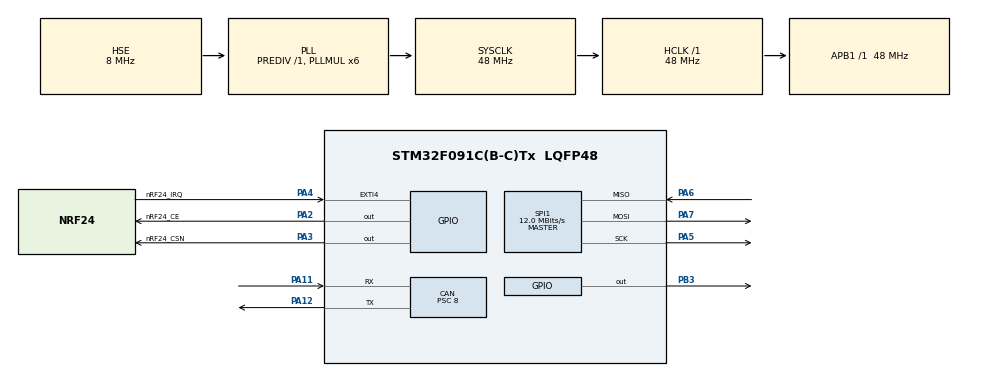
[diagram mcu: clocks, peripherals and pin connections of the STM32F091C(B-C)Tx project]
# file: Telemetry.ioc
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CAN.ABOM=ENABLE
CAN.BS1=CAN_BS1_16TQ
CAN.BS2=CAN_BS2_7TQ
CAN.CalculateTimeBit=4000
CAN.CalculateTimeQuantum=166.66666666666666
CAN.Prescaler=8
CAN.SJW=CAN_SJW_3TQ
Mcu.Family=STM32F0
Mcu.Name=STM32F091C(B-C)Tx
Mcu.Package=LQFP48
NVIC.CEC_CAN_IRQn=true\:0\:0\:false\:false\:true\:true
NVIC.TIM14_IRQn=true\:0\:0\:false\:false\:true\:true
NVIC.TIM16_IRQn=true\:0\:0\:false\:false\:true\:true
NVIC.TIM17_IRQn=true\:0\:0\:false\:false\:true\:true
PA11.Mode=Master
PA11.Signal=CAN_RX
PA12.Mode=Master
PA12.Signal=CAN_TX
PA2.GPIO_Label=nRF24_CE
PA2.GPIO_Speed=GPIO_SPEED_FREQ_HIGH
PA2.Signal=GPIO_Output
PA3.GPIO_Label=nRF24_CSN
PA3.GPIO_Speed=GPIO_SPEED_FREQ_HIGH
PA3.PinState=GPIO_PIN_SET
PA3.Signal=GPIO_Output
PA4.GPIO_Label=nRF24_IRQ
PA4.GPIO_ModeDefaultEXTI=GPIO_MODE_IT_FALLING
PA4.Signal=GPXTI4
PA5.Mode=Full_Duplex_Master
PA5.Signal=SPI1_SCK
PA6.Mode=Full_Duplex_Master
PA6.Signal=SPI1_MISO
PA7.Mode=Full_Duplex_Master
PA7.Signal=SPI1_MOSI
PB3.Signal=GPIO_Output
PF0-OSC_IN.Mode=HSE-External-Oscillator
PF0-OSC_IN.Signal=RCC_OSC_IN
PF1-OSC_OUT.Mode=HSE-External-Oscillator
PF1-OSC_OUT.Signal=RCC_OSC_OUT
ProjectManager.HeapSize=0x200
ProjectManager.StackSize=0x400
ProjectManager.TargetToolchain=TrueSTUDIO
RCC.AHBFreq_Value=48000000
RCC.APB1Freq_Value=48000000
RCC.APB1TimFreq_Value=48000000
RCC.EnbaleCSS=true
RCC.HCLKFreq_Value=48000000
RCC.PLLMUL=RCC_PLL_MUL6
RCC.PLLSourceVirtual=RCC_PLLSOURCE_HSE
RCC.SYSCLKFreq_VALUE=48000000
RCC.SYSCLKSource=RCC_SYSCLKSOURCE_PLLCLK
SPI1.BaudRatePrescaler=SPI_BAUDRATEPRESCALER_4
SPI1.CalculateBaudRate=12.0 MBits/s
SPI1.DataSize=SPI_DATASIZE_8BIT
SPI1.Direction=SPI_DIRECTION_2LINES
SPI1.Mode=SPI_MODE_MASTER
SPI1.VirtualType=VM_MASTER
TIM14.ClockDivision=TIM_CLOCKDIVISION_DIV4
TIM14.Period=999
TIM14.Prescaler=11
TIM16.ClockDivision=TIM_CLOCKDIVISION_DIV4
TIM16.Period=9999
TIM16.Prescaler=11
TIM17.ClockDivision=TIM_CLOCKDIVISION_DIV4
TIM17.Period=499
TIM17.Prescaler=11
VP_TIM14_VS_ClockSourceINT.Mode=Enable_Timer
VP_TIM16_VS_ClockSourceINT.Mode=Enable_Timer
VP_TIM17_VS_ClockSourceINT.Mode=Enable_Timer
board=Telemetry

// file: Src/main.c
/**
  ******************************************************************************
  * File Name          : main.c
  * Description        : Main program body
  ******************************************************************************
  ** This notice applies to any and all portions of this file
  * that are not between comment pairs USER CODE BEGIN and
  * USER CODE END. Other portions of this file, whether
  * inserted by the user or by software development tools
  * are owned by their respective copyright owners.
  *
  * COPYRIGHT(c) 2017 STMicroelectronics
  *
  * Redistribution and use in source and binary forms, with or without modification,
  * are permitted provided that the following conditions are met:
  *   1. Redistributions of source code must retain the above copyright notice,
  *      this list of conditions and the following disclaimer.
  *   2. Redistributions in binary form must reproduce the above copyright notice,
  *      this list of conditions and the following disclaimer in the documentation
  *      and/or other materials provided with the distribution.
  *   3. Neither the name of STMicroelectronics nor the names of its contributors
  *      may be used to endorse or promote products derived from this software
  *      without specific prior written permission.
  *
  * THIS SOFTWARE IS PROVIDED BY THE COPYRIGHT HOLDERS AND CONTRIBUTORS "AS IS"
  * AND ANY EXPRESS OR IMPLIED WARRANTIES, INCLUDING, BUT NOT LIMITED TO, THE
  * IMPLIED WARRANTIES OF MERCHANTABILITY AND FITNESS FOR A PARTICULAR PURPOSE ARE
  * DISCLAIMED. IN NO EVENT SHALL THE COPYRIGHT HOLDER OR CONTRIBUTORS BE LIABLE
  * FOR ANY DIRECT, INDIRECT, INCIDENTAL, SPECIAL, EXEMPLARY, OR CONSEQUENTIAL
  * DAMAGES (INCLUDING, BUT NOT LIMITED TO, PROCUREMENT OF SUBSTITUTE GOODS OR
  * SERVICES; LOSS OF USE, DATA, OR PROFITS; OR BUSINESS INTERRUPTION) HOWEVER
  * CAUSED AND ON ANY THEORY OF LIABILITY, WHETHER IN CONTRACT, STRICT LIABILITY,
  * OR TORT (INCLUDING NEGLIGENCE OR OTHERWISE) ARISING IN ANY WAY OUT OF THE USE
  * OF THIS SOFTWARE, EVEN IF ADVISED OF THE POSSIBILITY OF SUCH DAMAGE.
  *
  ******************************************************************************
  */
#include "main.h"
#include "stm32f0xx_hal.h"
#include "can.h"
#include "spi.h"
#include "tim.h"
#include "gpio.h"

/* USER CODE BEGIN Includes */
#include "m_wireless.h"
/* USER CODE END Includes */

/* USER CODE BEGIN PV */
/* Private variables ---------------------------------------------------------*/

/* USER CODE END PV */

void SystemClock_Config(void);

/* USER CODE BEGIN PFP */
/* Private function prototypes -----------------------------------------------*/

/* USER CODE END PFP */

int main(void)
{

  /* MCU Configuration----------------------------------------------------------*/

  /* Reset of all peripherals, Initializes the Flash interface and the Systick. */
  HAL_Init();

  /* Configure the system clock */
  SystemClock_Config();

  /* Initialize all configured peripherals */
  MX_GPIO_Init();
  MX_SPI1_Init();
  MX_CAN_Init();
  MX_TIM17_Init();
  MX_TIM14_Init();
  MX_TIM16_Init();

  /* Infinite loop */
  while (1)
  {

  }

}

/** System Clock Configuration
*/
void SystemClock_Config(void)
{

  RCC_OscInitTypeDef RCC_OscInitStruct;
  RCC_ClkInitTypeDef RCC_ClkInitStruct;

    /**Initializes the CPU, AHB and APB busses clocks
    */
  RCC_OscInitStruct.OscillatorType = RCC_OSCILLATORTYPE_HSE;
  RCC_OscInitStruct.HSEState = RCC_HSE_ON;
  RCC_OscInitStruct.HSIState = RCC_HSI_ON;
  RCC_OscInitStruct.PLL.PLLState = RCC_PLL_ON;
  RCC_OscInitStruct.PLL.PLLSource = RCC_PLLSOURCE_HSE;
  RCC_OscInitStruct.PLL.PLLMUL = RCC_PLL_MUL6;
  RCC_OscInitStruct.PLL.PREDIV = RCC_PREDIV_DIV1;
  if (HAL_RCC_OscConfig(&RCC_OscInitStruct) != HAL_OK)
  {
    _Error_Handler(__FILE__, __LINE__);
  }

    /**Initializes the CPU, AHB and APB busses clocks
    */
  RCC_ClkInitStruct.ClockType = RCC_CLOCKTYPE_HCLK|RCC_CLOCKTYPE_SYSCLK
                              |RCC_CLOCKTYPE_PCLK1;
  RCC_ClkInitStruct.SYSCLKSource = RCC_SYSCLKSOURCE_PLLCLK;
  RCC_ClkInitStruct.AHBCLKDivider = RCC_SYSCLK_DIV1;
  RCC_ClkInitStruct.APB1CLKDivider = RCC_HCLK_DIV1;

  if (HAL_RCC_ClockConfig(&RCC_ClkInitStruct, FLASH_LATENCY_1) != HAL_OK)
  {
    _Error_Handler(__FILE__, __LINE__);
  }

    /**Enables the Clock Security System
    */
  HAL_RCC_EnableCSS();

    /**Configure the Systick interrupt time
    */
  HAL_SYSTICK_Config(HAL_RCC_GetHCLKFreq()/1000);

    /**Configure the Systick
    */
  HAL_SYSTICK_CLKSourceConfig(SYSTICK_CLKSOURCE_HCLK);

  /* SysTick_IRQn interrupt configuration */
  HAL_NVIC_SetPriority(SysTick_IRQn, 0, 0);
}

void _Error_Handler(char * file, int line)
{
  while(1)
  {
  }
}

/************************ (C) COPYRIGHT STMicroelectronics *****END OF FILE****/
